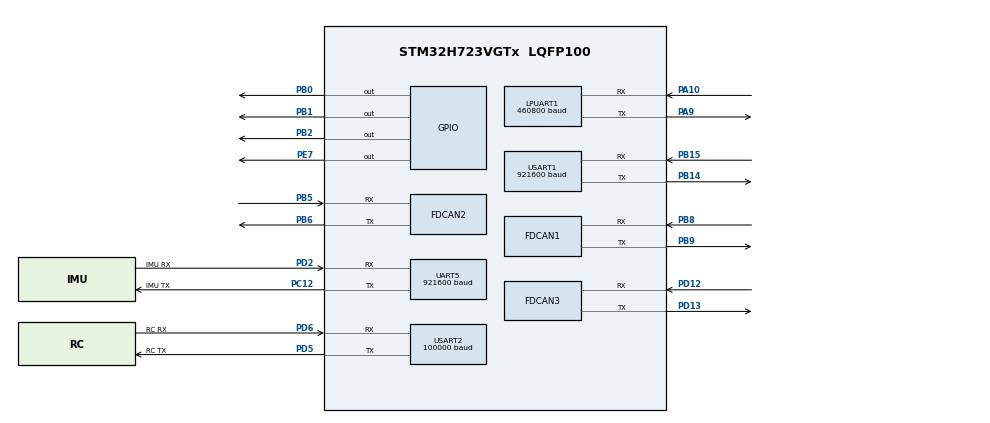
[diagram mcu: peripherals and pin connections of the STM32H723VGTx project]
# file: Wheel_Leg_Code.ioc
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Bdma.LPUART1_RX.0.Direction=DMA_PERIPH_TO_MEMORY
Bdma.LPUART1_RX.0.EventEnable=DISABLE
Bdma.LPUART1_RX.0.Instance=BDMA_Channel0
Bdma.LPUART1_RX.0.MemDataAlignment=DMA_MDATAALIGN_BYTE
Bdma.LPUART1_RX.0.MemInc=DMA_MINC_ENABLE
Bdma.LPUART1_RX.0.Mode=DMA_NORMAL
Bdma.LPUART1_RX.0.PeriphDataAlignment=DMA_PDATAALIGN_BYTE
Bdma.LPUART1_RX.0.PeriphInc=DMA_PINC_DISABLE
Bdma.LPUART1_RX.0.Polarity=HAL_DMAMUX_REQ_GEN_RISING
Bdma.LPUART1_RX.0.Priority=DMA_PRIORITY_LOW
Bdma.LPUART1_RX.0.RequestNumber=1
Bdma.LPUART1_RX.0.SignalID=NONE
Bdma.LPUART1_RX.0.SyncEnable=DISABLE
Bdma.LPUART1_RX.0.SyncPolarity=HAL_DMAMUX_SYNC_NO_EVENT
Bdma.LPUART1_RX.0.SyncRequestNumber=1
Bdma.LPUART1_RX.0.SyncSignalID=NONE
Bdma.LPUART1_TX.1.Direction=DMA_MEMORY_TO_PERIPH
Bdma.LPUART1_TX.1.EventEnable=DISABLE
Bdma.LPUART1_TX.1.Instance=BDMA_Channel1
Bdma.LPUART1_TX.1.MemDataAlignment=DMA_MDATAALIGN_BYTE
Bdma.LPUART1_TX.1.MemInc=DMA_MINC_ENABLE
Bdma.LPUART1_TX.1.Mode=DMA_NORMAL
Bdma.LPUART1_TX.1.PeriphDataAlignment=DMA_PDATAALIGN_BYTE
Bdma.LPUART1_TX.1.PeriphInc=DMA_PINC_DISABLE
Bdma.LPUART1_TX.1.Polarity=HAL_DMAMUX_REQ_GEN_RISING
Bdma.LPUART1_TX.1.Priority=DMA_PRIORITY_LOW
Bdma.LPUART1_TX.1.RequestNumber=1
Bdma.LPUART1_TX.1.SignalID=NONE
Bdma.LPUART1_TX.1.SyncEnable=DISABLE
Bdma.LPUART1_TX.1.SyncPolarity=HAL_DMAMUX_SYNC_NO_EVENT
Bdma.LPUART1_TX.1.SyncRequestNumber=1
Bdma.LPUART1_TX.1.SyncSignalID=NONE
Bdma.Request0=LPUART1_RX
Bdma.Request1=LPUART1_TX
Bdma.RequestsNb=2
CORTEX_M7.default_mode_Activation=1
Dma.Request0=USART2_RX
Dma.Request1=UART5_RX
Dma.Request2=USART1_RX
Dma.Request3=USART1_TX
Dma.UART5_RX.1.Direction=DMA_PERIPH_TO_MEMORY
Dma.UART5_RX.1.EventEnable=DISABLE
Dma.UART5_RX.1.FIFOMode=DMA_FIFOMODE_DISABLE
Dma.UART5_RX.1.Instance=DMA1_Stream1
Dma.UART5_RX.1.MemDataAlignment=DMA_MDATAALIGN_BYTE
Dma.UART5_RX.1.MemInc=DMA_MINC_ENABLE
Dma.UART5_RX.1.Mode=DMA_NORMAL
Dma.UART5_RX.1.PeriphDataAlignment=DMA_PDATAALIGN_BYTE
Dma.UART5_RX.1.PeriphInc=DMA_PINC_DISABLE
Dma.UART5_RX.1.Polarity=HAL_DMAMUX_REQ_GEN_RISING
Dma.UART5_RX.1.Priority=DMA_PRIORITY_LOW
Dma.UART5_RX.1.RequestNumber=1
Dma.UART5_RX.1.SignalID=NONE
Dma.UART5_RX.1.SyncEnable=DISABLE
Dma.UART5_RX.1.SyncPolarity=HAL_DMAMUX_SYNC_NO_EVENT
Dma.UART5_RX.1.SyncRequestNumber=1
Dma.UART5_RX.1.SyncSignalID=NONE
Dma.USART1_RX.2.Direction=DMA_PERIPH_TO_MEMORY
Dma.USART1_RX.2.EventEnable=DISABLE
Dma.USART1_RX.2.FIFOMode=DMA_FIFOMODE_DISABLE
Dma.USART1_RX.2.Instance=DMA1_Stream0
Dma.USART1_RX.2.MemDataAlignment=DMA_MDATAALIGN_BYTE
Dma.USART1_RX.2.MemInc=DMA_MINC_ENABLE
Dma.USART1_RX.2.Mode=DMA_NORMAL
Dma.USART1_RX.2.PeriphDataAlignment=DMA_PDATAALIGN_BYTE
Dma.USART1_RX.2.PeriphInc=DMA_PINC_DISABLE
Dma.USART1_RX.2.Polarity=HAL_DMAMUX_REQ_GEN_RISING
Dma.USART1_RX.2.Priority=DMA_PRIORITY_LOW
Dma.USART1_RX.2.RequestNumber=1
Dma.USART1_RX.2.SignalID=NONE
Dma.USART1_RX.2.SyncEnable=DISABLE
Dma.USART1_RX.2.SyncPolarity=HAL_DMAMUX_SYNC_NO_EVENT
Dma.USART1_RX.2.SyncRequestNumber=1
Dma.USART1_RX.2.SyncSignalID=NONE
Dma.USART1_TX.3.Direction=DMA_MEMORY_TO_PERIPH
Dma.USART1_TX.3.EventEnable=DISABLE
Dma.USART1_TX.3.FIFOMode=DMA_FIFOMODE_DISABLE
Dma.USART1_TX.3.Instance=DMA1_Stream2
Dma.USART1_TX.3.MemDataAlignment=DMA_MDATAALIGN_BYTE
Dma.USART1_TX.3.MemInc=DMA_MINC_ENABLE
Dma.USART1_TX.3.Mode=DMA_NORMAL
Dma.USART1_TX.3.PeriphDataAlignment=DMA_PDATAALIGN_BYTE
Dma.USART1_TX.3.PeriphInc=DMA_PINC_DISABLE
Dma.USART1_TX.3.Polarity=HAL_DMAMUX_REQ_GEN_RISING
Dma.USART1_TX.3.Priority=DMA_PRIORITY_LOW
Dma.USART1_TX.3.RequestNumber=1
Dma.USART1_TX.3.SignalID=NONE
Dma.USART1_TX.3.SyncEnable=DISABLE
Dma.USART1_TX.3.SyncPolarity=HAL_DMAMUX_SYNC_NO_EVENT
Dma.USART1_TX.3.SyncRequestNumber=1
Dma.USART1_TX.3.SyncSignalID=NONE
Dma.USART2_RX.0.Direction=DMA_PERIPH_TO_MEMORY
Dma.USART2_RX.0.EventEnable=DISABLE
Dma.USART2_RX.0.FIFOMode=DMA_FIFOMODE_DISABLE
Dma.USART2_RX.0.Instance=DMA1_Stream6
Dma.USART2_RX.0.MemDataAlignment=DMA_MDATAALIGN_BYTE
Dma.USART2_RX.0.MemInc=DMA_MINC_ENABLE
Dma.USART2_RX.0.Mode=DMA_CIRCULAR
Dma.USART2_RX.0.PeriphDataAlignment=DMA_PDATAALIGN_BYTE
Dma.USART2_RX.0.PeriphInc=DMA_PINC_DISABLE
Dma.USART2_RX.0.Polarity=HAL_DMAMUX_REQ_GEN_RISING
Dma.USART2_RX.0.Priority=DMA_PRIORITY_LOW
Dma.USART2_RX.0.RequestNumber=1
Dma.USART2_RX.0.SignalID=NONE
Dma.USART2_RX.0.SyncEnable=DISABLE
Dma.USART2_RX.0.SyncPolarity=HAL_DMAMUX_SYNC_NO_EVENT
Dma.USART2_RX.0.SyncRequestNumber=1
Dma.USART2_RX.0.SyncSignalID=NONE
FDCAN1.AutoRetransmission=ENABLE
FDCAN1.CalculateBaudRateNominal=1000000
FDCAN1.CalculateTimeBitNominal=1000
FDCAN1.CalculateTimeQuantumNominal=12.5
FDCAN1.DataSyncJumpWidth=4
FDCAN1.DataTimeSeg1=15
FDCAN1.DataTimeSeg2=4
FDCAN1.FrameFormat=FDCAN_FRAME_FD_BRS
FDCAN1.NominalPrescaler=1
FDCAN1.NominalSyncJumpWidth=16
FDCAN1.NominalTimeSeg1=63
FDCAN1.NominalTimeSeg2=16
FDCAN1.RxFifo0ElmtsNbr=16
FDCAN1.StdFiltersNbr=4
FDCAN1.TxFifoQueueElmtsNbr=8
FDCAN2.AutoRetransmission=ENABLE
FDCAN2.CalculateBaudRateNominal=1000000
FDCAN2.CalculateTimeBitNominal=1000
FDCAN2.CalculateTimeQuantumNominal=12.5
FDCAN2.MessageRAMOffset=128
FDCAN2.NominalPrescaler=1
FDCAN2.NominalSyncJumpWidth=16
FDCAN2.NominalTimeSeg1=63
FDCAN2.NominalTimeSeg2=16
FDCAN2.RxFifo0ElmtsNbr=16
FDCAN2.StdFiltersNbr=4
FDCAN2.TxFifoQueueElmtsNbr=8
FDCAN3.AutoRetransmission=ENABLE
FDCAN3.CalculateBaudRateNominal=1000000
FDCAN3.CalculateTimeBitNominal=1000
FDCAN3.CalculateTimeQuantumNominal=12.5
FDCAN3.DataSyncJumpWidth=16
FDCAN3.MessageRAMOffset=256
FDCAN3.NominalPrescaler=1
FDCAN3.NominalTimeSeg1=63
FDCAN3.NominalTimeSeg2=16
FDCAN3.RxFifo0ElmtsNbr=16
FDCAN3.StdFiltersNbr=4
FDCAN3.TxFifoQueueElmtsNbr=8
FREERTOS.Tasks01=InitTask,55,2048,StartInitTask,As weak,NULL,Dynamic,NULL,NULL;VofaTask,24,1024,StartVofaTask,As weak,NULL,Dynamic,NULL,NULL;ControlTask,24,4096,StartControlTask,As weak,NULL,Dynamic,NULL,NULL;EstimatorTask,24,8192,StartEstimatorTask,As weak,NULL,Dynamic,NULL,NULL;Tinympc14Task,24,4096,StartTinympc14Task,As weak,NULL,Static,Tinympc14TaskBuffer,Tinympc14TaskControlBlock;RadarTask,24,512,StartRadarTask,As weak,NULL,Dynamic,NULL,NULL
FREERTOS.configENABLE_FPU=1
FREERTOS.configTOTAL_HEAP_SIZE=114688
LPUART1.BaudRate=460800
Mcu.Family=STM32H7
Mcu.Name=STM32H723VGTx
Mcu.Package=LQFP100
NVIC.BDMA_Channel0_IRQn=true\:5\:0\:false\:false\:true\:true\:false\:true\:true
NVIC.BDMA_Channel1_IRQn=true\:5\:0\:false\:false\:true\:true\:false\:true\:true
NVIC.CORDIC_IRQn=true\:5\:0\:false\:false\:true\:true\:true\:true\:true
NVIC.DMA1_Stream0_IRQn=true\:5\:0\:false\:false\:true\:true\:false\:true\:true
NVIC.DMA1_Stream1_IRQn=true\:5\:0\:false\:false\:true\:true\:false\:true\:true
NVIC.DMA1_Stream2_IRQn=true\:5\:0\:false\:false\:true\:true\:false\:true\:true
NVIC.DMA1_Stream6_IRQn=true\:5\:0\:false\:false\:true\:true\:false\:true\:true
NVIC.FDCAN1_IT0_IRQn=true\:5\:0\:false\:false\:true\:true\:true\:true\:true
NVIC.FDCAN2_IT0_IRQn=true\:5\:0\:false\:false\:true\:true\:true\:true\:true
NVIC.FDCAN3_IT0_IRQn=true\:5\:0\:false\:false\:true\:true\:true\:true\:true
NVIC.LPUART1_IRQn=true\:5\:0\:false\:false\:true\:true\:true\:true\:true
NVIC.PriorityGroup=NVIC_PRIORITYGROUP_4
NVIC.TIM6_DAC_IRQn=true\:15\:0\:false\:false\:true\:false\:false\:true\:true
NVIC.TimeBase=TIM6_DAC_IRQn
NVIC.TimeBaseIP=TIM6
NVIC.UART5_IRQn=true\:5\:0\:false\:false\:true\:true\:true\:true\:true
NVIC.USART1_IRQn=true\:5\:0\:false\:false\:true\:true\:true\:true\:true
NVIC.USART2_IRQn=true\:5\:0\:false\:false\:true\:true\:true\:true\:true
PA10.Mode=Asynchronous
PA10.Signal=LPUART1_RX
PA9.Mode=Asynchronous
PA9.Signal=LPUART1_TX
PB0.GPIO_PuPd=GPIO_PULLUP
PB0.Signal=GPIO_Output
PB1.GPIO_PuPd=GPIO_PULLUP
PB1.Signal=GPIO_Output
PB14.Mode=Asynchronous
PB14.Signal=USART1_TX
PB15.Mode=Asynchronous
PB15.Signal=USART1_RX
PB2.GPIO_PuPd=GPIO_PULLUP
PB2.Signal=GPIO_Output
PB5.Mode=FDCAN_Activate
PB5.Signal=FDCAN2_RX
PB6.Mode=FDCAN_Activate
PB6.Signal=FDCAN2_TX
PB8.Mode=FDCAN_Activate
PB8.Signal=FDCAN1_RX
PB9.Mode=FDCAN_Activate
PB9.Signal=FDCAN1_TX
PC12.GPIO_Label=IMU TX
PC12.Mode=Asynchronous
PC12.Signal=UART5_TX
PD12.Mode=FDCAN_Activate
PD12.Signal=FDCAN3_RX
PD13.Mode=FDCAN_Activate
PD13.Signal=FDCAN3_TX
PD2.GPIO_Label=IMU RX
PD2.Mode=Asynchronous
PD2.Signal=UART5_RX
PD5.GPIO_Label=RC TX
PD5.Mode=Asynchronous
PD5.Signal=USART2_TX
PD6.GPIO_Label=RC RX
PD6.Mode=Asynchronous
PD6.Signal=USART2_RX
PE7.GPIO_PuPd=GPIO_PULLUP
PE7.Signal=GPIO_Output
PH0-OSC_IN.Mode=HSE-External-Oscillator
PH0-OSC_IN.Signal=RCC_OSC_IN
PH1-OSC_OUT.Mode=HSE-External-Oscillator
PH1-OSC_OUT.Signal=RCC_OSC_OUT
ProjectManager.HeapSize=0x200
ProjectManager.StackSize=0x400
ProjectManager.TargetToolchain=MDK-ARM V5.32
RCC.ADCFreq_Value=240000000
RCC.APB1Freq_Value=137500000
RCC.APB2Freq_Value=137500000
RCC.APB3Freq_Value=137500000
RCC.APB4Freq_Value=137500000
RCC.CortexFreq_Value=550000000
RCC.D1PPRE=RCC_APB3_DIV2
RCC.D2PPRE1=RCC_APB1_DIV2
RCC.D2PPRE2=RCC_APB2_DIV2
RCC.D3PPRE=RCC_APB4_DIV2
RCC.DIVM1=12
RCC.DIVM2=3
RCC.DIVM3=3
RCC.DIVN1=275
RCC.DIVN2=60
RCC.DIVN3=60
RCC.DIVP1=1
RCC.DIVQ2=6
RCC.FDCANCLockSelection=RCC_FDCANCLKSOURCE_PLL2
RCC.HCLKFreq_Value=275000000
RCC.HPRE=RCC_HCLK_DIV2
RCC.HSE_VALUE=24000000
RCC.PLL2FRACN=0
RCC.PLL3FRACN=0
RCC.PLLFRACN=0
RCC.PLLSourceVirtual=RCC_PLLSOURCE_HSE
RCC.SPI6CLockSelection=RCC_SPI6CLKSOURCE_HSE
RCC.SYSCLKFreq_VALUE=550000000
RCC.SYSCLKSource=RCC_SYSCLKSOURCE_PLLCLK
RCC.SupplySource=PWR_EXTERNAL_SOURCE_SUPPLY
RCC.USBFreq_Value=275000000
UART5.BaudRate=921600
USART1.BaudRate=921600
USART1.VirtualMode-Asynchronous=VM_ASYNC
USART2.BaudRate=100000
USART2.Parity=PARITY_EVEN
USART2.VirtualMode-Asynchronous=VM_ASYNC
USART2.WordLength=WORDLENGTH_9B
VP_CORDIC_VS_CORDIC.Mode=CORDIC_Activate
VP_FMAC_VS_FMAC.Mode=FMAC_Activate
VP_FREERTOS_VS_CMSIS_V2.Mode=CMSIS_V2
VP_MEMORYMAP_VS_MEMORYMAP.Mode=CurAppReg
VP_SYS_VS_tim6.Mode=TIM6
board=custom

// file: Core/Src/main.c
/* USER CODE BEGIN Header */
/**
  ******************************************************************************
  * @file           : main.c
  * @brief          : Main program body
  ******************************************************************************
  * @attention
  *
  * Copyright (c) 2026 STMicroelectronics.
  * All rights reserved.
  *
  * This software is licensed under terms that can be found in the LICENSE file
  * in the root directory of this software component.
  * If no LICENSE file comes with this software, it is provided AS-IS.
  *
  ******************************************************************************
  */
/* USER CODE END Header */
#include "main.h"
#include "cmsis_os.h"
#include "bdma.h"
#include "cordic.h"
#include "dma.h"
#include "fdcan.h"
#include "fmac.h"
#include "usart.h"
#include "gpio.h"

void SystemClock_Config(void);
void PeriphCommonClock_Config(void);
static void MPU_Config(void);
void MX_FREERTOS_Init(void);

int main(void)
{

  /* MPU Configuration--------------------------------------------------------*/
  MPU_Config();

  /* MCU Configuration--------------------------------------------------------*/

  /* Reset of all peripherals, Initializes the Flash interface and the Systick. */
  HAL_Init();

  /* USER CODE BEGIN Init */
  SCB_EnableICache();

  /* USER CODE END Init */

  /* Configure the system clock */
  SystemClock_Config();

  /* Configure the peripherals common clocks */
  PeriphCommonClock_Config();

  /* Initialize all configured peripherals */
  MX_GPIO_Init();
  MX_DMA_Init();
  MX_BDMA_Init();
  MX_FDCAN1_Init();
  MX_FDCAN2_Init();
  MX_FDCAN3_Init();
  MX_USART1_UART_Init();
  MX_CORDIC_Init();
  MX_FMAC_Init();
  MX_UART5_Init();
  MX_LPUART1_UART_Init();
  MX_USART2_UART_Init();

  /* Init scheduler */
  osKernelInitialize();  /* Call init function for freertos objects (in cmsis_os2.c) */
  MX_FREERTOS_Init();

  /* Start scheduler */
  osKernelStart();

  /* We should never get here as control is now taken by the scheduler */

  /* Infinite loop */
  while (1)
  {

  }
}

void SystemClock_Config(void)
{
  RCC_OscInitTypeDef RCC_OscInitStruct = {0};
  RCC_ClkInitTypeDef RCC_ClkInitStruct = {0};

  /** Supply configuration update enable
  */
  HAL_PWREx_ConfigSupply(PWR_EXTERNAL_SOURCE_SUPPLY);

  /** Configure the main internal regulator output voltage
  */
  __HAL_PWR_VOLTAGESCALING_CONFIG(PWR_REGULATOR_VOLTAGE_SCALE0);

  while(!__HAL_PWR_GET_FLAG(PWR_FLAG_VOSRDY)) {}

  /** Initializes the RCC Oscillators according to the specified parameters
  * in the RCC_OscInitTypeDef structure.
  */
  RCC_OscInitStruct.OscillatorType = RCC_OSCILLATORTYPE_HSE;
  RCC_OscInitStruct.HSEState = RCC_HSE_ON;
  RCC_OscInitStruct.PLL.PLLState = RCC_PLL_ON;
  RCC_OscInitStruct.PLL.PLLSource = RCC_PLLSOURCE_HSE;
  RCC_OscInitStruct.PLL.PLLM = 12;
  RCC_OscInitStruct.PLL.PLLN = 275;
  RCC_OscInitStruct.PLL.PLLP = 1;
  RCC_OscInitStruct.PLL.PLLQ = 2;
  RCC_OscInitStruct.PLL.PLLR = 2;
  RCC_OscInitStruct.PLL.PLLRGE = RCC_PLL1VCIRANGE_1;
  RCC_OscInitStruct.PLL.PLLVCOSEL = RCC_PLL1VCOWIDE;
  RCC_OscInitStruct.PLL.PLLFRACN = 0;
  if (HAL_RCC_OscConfig(&RCC_OscInitStruct) != HAL_OK)
  {
    Error_Handler();
  }

  /** Initializes the CPU, AHB and APB buses clocks
  */
  RCC_ClkInitStruct.ClockType = RCC_CLOCKTYPE_HCLK|RCC_CLOCKTYPE_SYSCLK
                              |RCC_CLOCKTYPE_PCLK1|RCC_CLOCKTYPE_PCLK2
                              |RCC_CLOCKTYPE_D3PCLK1|RCC_CLOCKTYPE_D1PCLK1;
  RCC_ClkInitStruct.SYSCLKSource = RCC_SYSCLKSOURCE_PLLCLK;
  RCC_ClkInitStruct.SYSCLKDivider = RCC_SYSCLK_DIV1;
  RCC_ClkInitStruct.AHBCLKDivider = RCC_HCLK_DIV2;
  RCC_ClkInitStruct.APB3CLKDivider = RCC_APB3_DIV2;
  RCC_ClkInitStruct.APB1CLKDivider = RCC_APB1_DIV2;
  RCC_ClkInitStruct.APB2CLKDivider = RCC_APB2_DIV2;
  RCC_ClkInitStruct.APB4CLKDivider = RCC_APB4_DIV2;

  if (HAL_RCC_ClockConfig(&RCC_ClkInitStruct, FLASH_LATENCY_3) != HAL_OK)
  {
    Error_Handler();
  }
}

void PeriphCommonClock_Config(void)
{
  RCC_PeriphCLKInitTypeDef PeriphClkInitStruct = {0};

  /** Initializes the peripherals clock
  */
  PeriphClkInitStruct.PeriphClockSelection = RCC_PERIPHCLK_FDCAN;
  PeriphClkInitStruct.PLL2.PLL2M = 3;
  PeriphClkInitStruct.PLL2.PLL2N = 60;
  PeriphClkInitStruct.PLL2.PLL2P = 2;
  PeriphClkInitStruct.PLL2.PLL2Q = 6;
  PeriphClkInitStruct.PLL2.PLL2R = 2;
  PeriphClkInitStruct.PLL2.PLL2RGE = RCC_PLL2VCIRANGE_3;
  PeriphClkInitStruct.PLL2.PLL2VCOSEL = RCC_PLL2VCOWIDE;
  PeriphClkInitStruct.PLL2.PLL2FRACN = 0;
  PeriphClkInitStruct.FdcanClockSelection = RCC_FDCANCLKSOURCE_PLL2;
  if (HAL_RCCEx_PeriphCLKConfig(&PeriphClkInitStruct) != HAL_OK)
  {
    Error_Handler();
  }
}

 /* MPU Configuration */

void MPU_Config(void)
{
  MPU_Region_InitTypeDef MPU_InitStruct = {0};

  /* Disables the MPU */
  HAL_MPU_Disable();

  /** Initializes and configures the Region and the memory to be protected
  */
  MPU_InitStruct.Enable = MPU_REGION_ENABLE;
  MPU_InitStruct.Number = MPU_REGION_NUMBER0;
  MPU_InitStruct.BaseAddress = 0x0;
  MPU_InitStruct.Size = MPU_REGION_SIZE_4GB;
  MPU_InitStruct.SubRegionDisable = 0x87;
  MPU_InitStruct.TypeExtField = MPU_TEX_LEVEL0;
  MPU_InitStruct.AccessPermission = MPU_REGION_NO_ACCESS;
  MPU_InitStruct.DisableExec = MPU_INSTRUCTION_ACCESS_DISABLE;
  MPU_InitStruct.IsShareable = MPU_ACCESS_SHAREABLE;
  MPU_InitStruct.IsCacheable = MPU_ACCESS_NOT_CACHEABLE;
  MPU_InitStruct.IsBufferable = MPU_ACCESS_NOT_BUFFERABLE;

  HAL_MPU_ConfigRegion(&MPU_InitStruct);
  /* Enables the MPU */
  HAL_MPU_Enable(MPU_PRIVILEGED_DEFAULT);

}

void HAL_TIM_PeriodElapsedCallback(TIM_HandleTypeDef *htim)
{
  if (htim->Instance == TIM6)
  {
    HAL_IncTick();
  }
}

void Error_Handler(void)
{
  __disable_irq();
  while (1)
  {
  }
}
